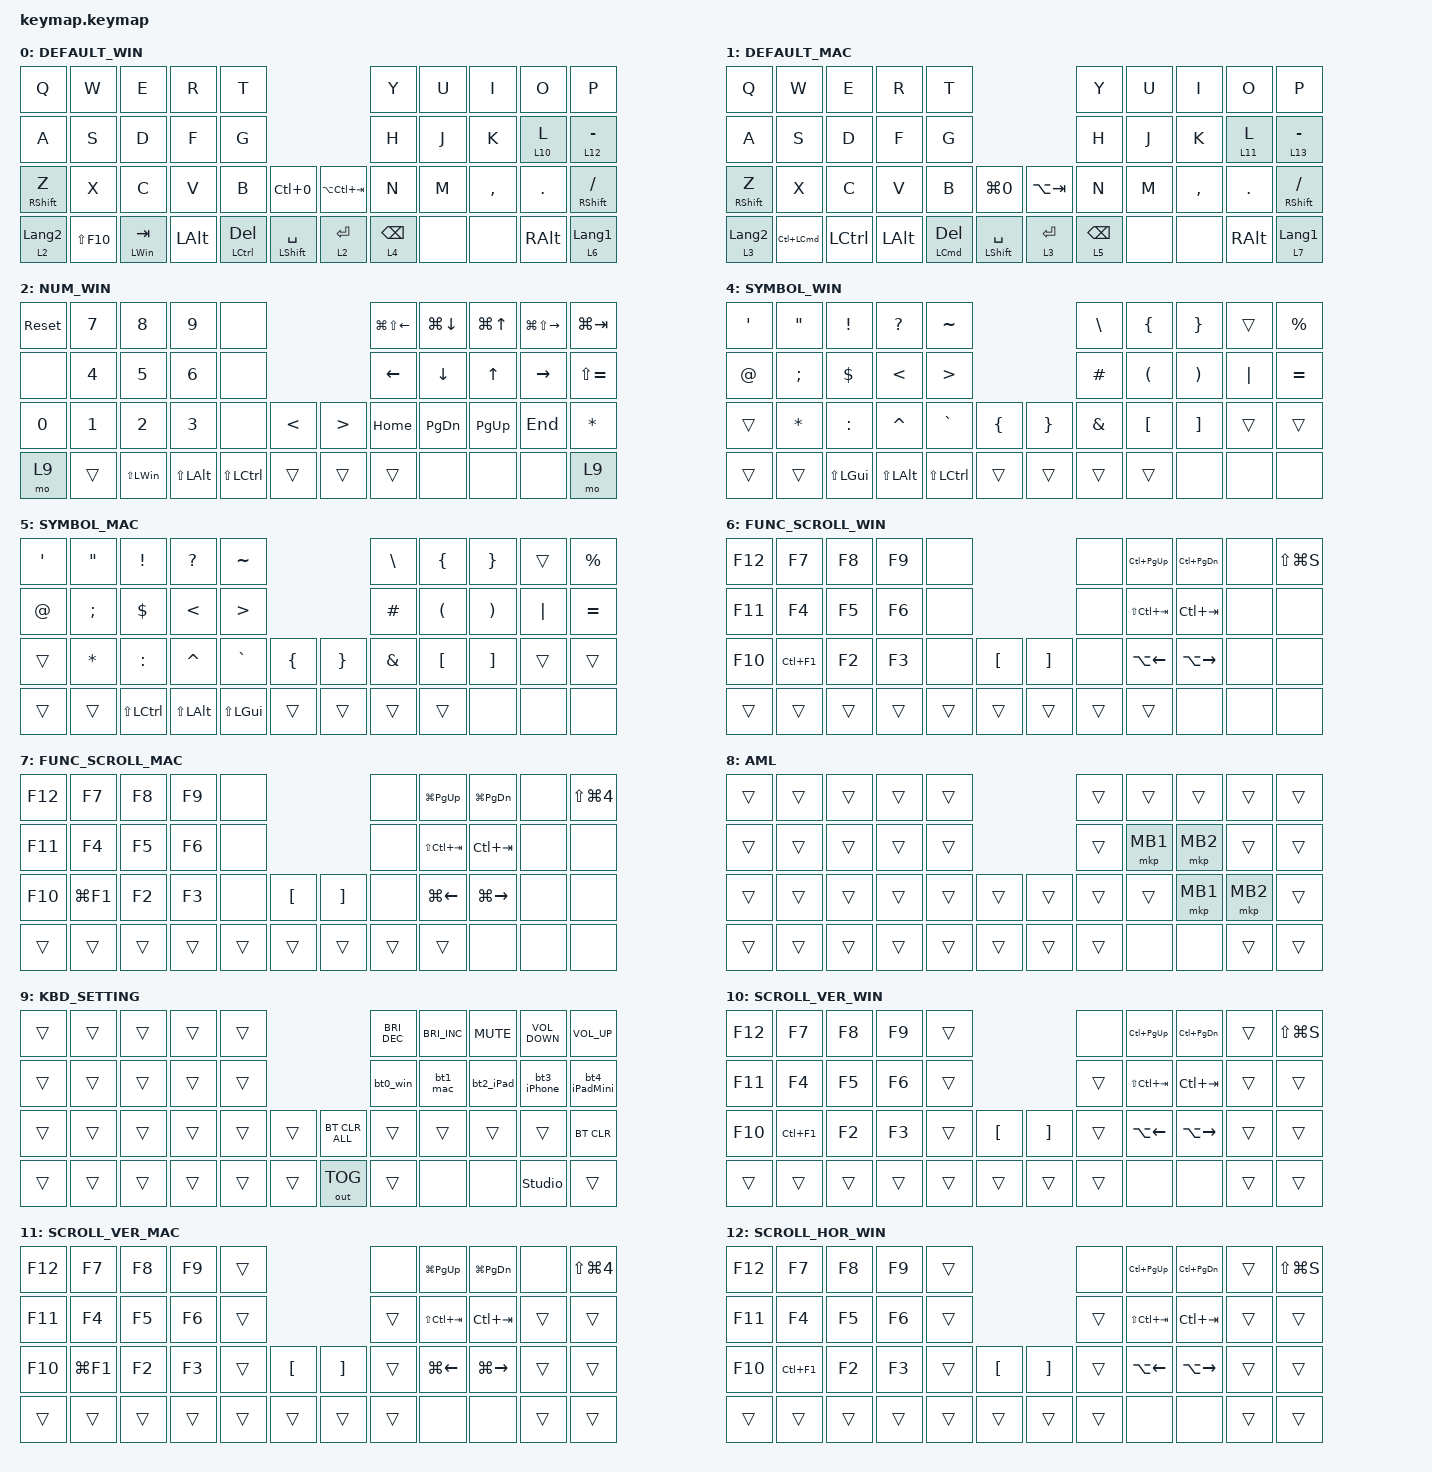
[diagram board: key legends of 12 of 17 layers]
#include <dt-bindings/zmk/input_transform.h>
#include <input/processors.dtsi>
#include <input/processors/report_rate_limit.dtsi>
#include <scroll-snap.dtsi>
#include "elpekenin/behaviors.dtsi"
#include <behaviors/input_gestures_accel.dtsi>
#include <behaviors/runtime_macro.dtsi>
#include <behaviors.dtsi>
#include <dt-bindings/zmk/bt.h>
#include <dt-bindings/zmk/keys.h>
#include <dt-bindings/zmk/outputs.h>
#include <dt-bindings/zmk/pointing.h>

#define DEFAULT_WIN 0
#define DEFAULT_MAC 1
#define NUM_WIN 2
#define NUM_MAC 3
#define SYMBOL_WIN 4
#define SYMBOL_MAC 5
#define FUNC_SCROLL_WIN 6
#define FUNC_SCROLL_MAC 7
#define AML 8
#define KBD_SETTING 9
#define SCROLL_VER_WIN 10
#define SCROLL_VER_MAC 11
#define SCROLL_HOR_WIN 12
#define SCROLL_HOR_MAC 13
#define GESTURE_WIN 14
#define GESTURE_MAC 15
#define WIN_SCROLL_DIR 16

#undef ZMK_POINTING_DEFAULT_SCRL_VAL

#define ZMK_POINTING_DEFAULT_SCRL_VAL 30

#define MOD_MORPH(NAME, NORMAL, MORPHED, MODS_VAL) \
    NAME: NAME { \
        compatible = "zmk,behavior-mod-morph"; \
        #binding-cells = <0>; \
        bindings = <NORMAL>, <MORPHED>; \
        mods = <MODS_VAL>; \
    };
#define MOD_MORPH_KEEP(NAME, NORMAL, MORPHED, MODS_VAL, KEEP_VAL) \
    NAME: NAME { \
        compatible = "zmk,behavior-mod-morph"; \
        #binding-cells = <0>; \
        bindings = <NORMAL>, <MORPHED>; \
        mods = <MODS_VAL>; \
        keep-mods = <KEEP_VAL>; \
    };

// XSレイアウト（Sレイアウト, 44キー）を選択

// ZMK_KEYMAP_LEN uses the largest enabled physical layout's transform.
// This keymap only supports S; keep M/L available to other keymaps.
&physical_layout_m {
    status = "disabled";
};

&physical_layout_l {
    status = "disabled";
};

/ {
    chosen { zmk,physical-layout = &physical_layout_s; };

    /omit-if-no-ref/
    tb_scroll_runtime: tb_scroll_runtime {
        compatible = "zmk,input-processor-runtime";
        processor-label = "tbscrl";
        type = <INPUT_EV_REL>;
        x-codes = <INPUT_REL_HWHEEL>;
        y-codes = <INPUT_REL_WHEEL>;
        scale-multiplier = <1>;
        scale-divisor = <1>;
        rotation-degrees = <0>;
        track-remainders;
        #input-processor-cells = <0>;
    };
};

&zip_scroll_snap {
    x-threshold = <3 4>;
    y-threshold = <4 3>;
    xy-threshold = <3 4>;
    require-n-samples = <4>;
    immediate-snap-threshold = <800>;
    lock-duration-ms = <150>;
    lock-for-next-n-events = <4>;
    idle-reset-timeout-ms = <800>;
};

&mmv {
    delay-ms = <20>;
    time-to-max-speed-ms = <300>;
    acceleration-exponent = <2>;
};

&msc {
    delay-ms = <0>;
    time-to-max-speed-ms = <500>;
    acceleration-exponent = <2>;
};

&mkp_input_listener { input-processors = <&zip_temp_layer AML 250>; };

&mt {
    flavor = "balanced";
    tapping-term-ms = <180>;
    quick-tap-ms = <180>;
};

&lt {
    tapping-term-ms = <180>;
    quick-tap-ms = <180>;
};

&sl { release-after-ms = <30000>; };

// トラックボール入力リスナー設定（XY反転はハードウェア依存のため維持）

&pointing_listener {
    // レポートレート制限 + Threshold付きAML

    input-processors =
        <&zip_xy_transform (INPUT_TRANSFORM_X_INVERT | INPUT_TRANSFORM_Y_INVERT)>,
        <&zip_report_rate_limit 8>,
        <&zip_temp_layer_threshold AML 30000>,
        <&pointer_accel>,
        <&mouse_runtime_input_processor>;

    // 自由スクロール（Mac）

    scroller_mac {
        layers = <FUNC_SCROLL_MAC>;
        input-processors =
            <&zip_scroll_acceleration 6>,
            <&zip_xy_scaler 1 8>,
            <&zip_xy_transform INPUT_TRANSFORM_X_INVERT>,
            <&zip_xy_to_scroll_mapper>,
            <&tb_scroll_runtime>;

        // <&zip_scroll_snap>;
    };

    // 自由スクロール（Windows）

    scroller_win {
        layers = <FUNC_SCROLL_WIN>;
        input-processors =
            <&zip_scroll_acceleration 6>,
            <&zip_xy_scaler 1 2>,
            <&zip_xy_transform INPUT_TRANSFORM_Y_INVERT>,
            <&zip_xy_to_scroll_mapper>,
            <&tb_scroll_runtime>;

        // <&zip_scroll_snap>;
    };

    // 縦スクロール（Mac）

    scroller_mac_vertical {
        layers = <SCROLL_VER_MAC>;
        input-processors =
            <&zip_scroll_acceleration 6>,
            <&zip_y_scaler 1 8>,
            <&zip_x_scaler 0 1>,
            <&zip_xy_to_scroll_mapper>,
            <&tb_scroll_runtime>;
    };

    // 横スクロール（Mac）

    scroller_mac_horizontal {
        layers = <SCROLL_HOR_MAC>;
        input-processors =
            <&zip_scroll_acceleration 6>,
            <&zip_x_scaler 1 8>,
            <&zip_y_scaler 0 1>,
            <&zip_xy_transform INPUT_TRANSFORM_X_INVERT>,
            <&zip_xy_to_scroll_mapper>,
            <&tb_scroll_runtime>;
    };

    // 縦スクロール（Windows）

    scroller_win_vertical {
        layers = <SCROLL_VER_WIN>;
        input-processors =
            <&zip_scroll_acceleration 6>,
            <&zip_y_scaler 1 2>,
            <&zip_x_scaler 0 1>,
            <&zip_xy_transform INPUT_TRANSFORM_Y_INVERT>,
            <&zip_xy_to_scroll_mapper>,
            <&tb_scroll_runtime>;
    };

    // 横スクロール（Windows）

    scroller_win_horizontal {
        layers = <SCROLL_HOR_WIN>;
        input-processors =
            <&zip_scroll_acceleration 6>,
            <&zip_x_scaler 1 2>,
            <&zip_y_scaler 0 1>,
            <&zip_xy_to_scroll_mapper>,
            <&tb_scroll_runtime>;
    };

    // トラックボール→矢印キー変換（数字レイヤー）

    arrow_keys {
        layers = <NUM_WIN NUM_MAC>;
        input-processors = <&zip_arrow_keys>;
        process-next;
    };

    // 音量・輝度調整（KBD_SETTINGレイヤー）

    volume_keys {
        layers = <KBD_SETTING>;
        input-processors = <&zip_volume_keys>;
        process-next;
    };

    // カーソル無効（数字・設定レイヤー）

    post_volume_keys {
        layers = <NUM_WIN NUM_MAC KBD_SETTING>;
        input-processors = <&zip_xy_scaler 0 1>;
    };
};

/ {
    /omit-if-no-ref/

    zip_temp_layer: zip_temp_layer {
        compatible = "zmk,input-processor-temp-layer";
        #input-processor-cells = <2>;
        excluded-positions = <
            16  // J
            17  // K
            36  // Delete (Ctrl/Cmd+Del位置)
            37  // Space (Shift+Space位置)
        >;

        require-prior-idle-ms = <300>;
    };

    zip_temp_layer_threshold: zip_temp_layer_threshold {
        compatible = "zmk,input-processor-temp-layer-threshold";
        #input-processor-cells = <2>;
        threshold = <12>;
        excluded-positions = <
            16  // J
            17  // K
            29  // ,
            30  // .
            36  // Delete
            37  // Space
        >;

        require-prior-idle-ms = <0>;
        reset-timeout-ms = <200>;
    };

    zip_scroll_acceleration: zip_scroll_acceleration {
        compatible = "zmk,input-processor-scroll-acceleration";
        #input-processor-cells = <1>;
        decay-ms = <100>;
        max-acceleration = <20>;
        min-speed-threshold = <1>;
    };

    pointer_accel: pointer_accel {
        compatible = "zmk,input-processor-acceleration";
        #input-processor-cells = <0>;
        input-type = <INPUT_EV_REL>;
        codes = <INPUT_REL_X INPUT_REL_Y>;
    };

    zip_arrow_keys: zip_arrow_keys {
        compatible = "zmk,input-processor-keybind";
        #input-processor-cells = <0>;
        track_remainders;
        bindings = <&kp LEFT>, <&kp RIGHT>, <&kp DOWN>, <&kp UP>;

        tick = <10>;
        wait-ms = <5>;
        tap-ms = <5>;
        mode = <1>;
    };

    zip_volume_keys: zip_volume_keys {
        compatible = "zmk,input-processor-keybind";
        #input-processor-cells = <0>;
        track_remainders;
        bindings =
            <&kp C_VOLUME_DOWN>,
            <&kp C_VOLUME_UP>,
            <&kp C_BRIGHTNESS_DEC>,
            <&kp C_BRIGHTNESS_INC>;

        tick = <6>;                     // 低速時の感度を上げる（10→6: 少ない移動で1ステップ）
        wait-ms = <25>;                 // 高速時の連続発火を抑える（5→25: 一気に変化しすぎない）
        max_pending_activations = <3>;  // 1報告で貯まる上限を絞る（既定5→3: 高速時の上振れ抑制）
        tap-ms = <5>;
        mode = <1>;
    };

    combos {
        compatible = "zmk,combos";

        // S+D → Tab（roBa: 11+12 = S+D, torabo同じ）

        tab {
            bindings = <&kp TAB>;
            key-positions = <11 12>;
            timeout-ms = <80>;
        };

        // D+F → Shift+Tab

        shift_tab {
            bindings = <&kp LS(TAB)>;
            key-positions = <12 13>;
            timeout-ms = <80>;
        };

        // Q+W → Escape

        Esc {
            bindings = <&kp ESCAPE>;
            key-positions = <0 1>;
            timeout-ms = <80>;
        };

        // J+K → 中クリック（roBa: 18+19, torabo: 16+17）

        middle_click {
            bindings = <&mkp MB3>;
            key-positions = <16 17>;
        };

        // A+S → CapsLock（roBa: 10+11, torabo同じ）

        caps_lock {
            bindings = <&kp CAPSLOCK>;
            key-positions = <10 11>;
        };

        middle_click_alt {
            bindings = <&mkp MB3>;
            key-positions = <29 30>;
        };
    };

    macros {
        to_layer_0: to_layer_0 {
            compatible = "zmk,behavior-macro-one-param";
            #binding-cells = <1>;
            bindings = <&to 0 &macro_param_1to1 &kp MACRO_PLACEHOLDER>;
            label = "TO_LAYER_0";
        };

        bt0_win: bt0 {
            compatible = "zmk,behavior-macro";
            #binding-cells = <0>;
            bindings =
                <&bt BT_SEL 0 &bt BT_DISC 1 &bt BT_DISC 2 &bt BT_DISC 3 &bt BT_DISC 4>,
                <&macro_wait_time 200>,
                <&df 0 &tog_on WIN_SCROLL_DIR>;

            label = "BT0";
        };

        bt1_mac: bt1 {
            compatible = "zmk,behavior-macro";
            #binding-cells = <0>;
            bindings =
                <&bt BT_SEL 1 &bt BT_DISC 0 &bt BT_DISC 2 &bt BT_DISC 3 &bt BT_DISC 4>,
                <&macro_wait_time 200>,
                <&df 1 &tog_off WIN_SCROLL_DIR>;

            label = "BT1";
        };

        bt2_iPad: bt2_iPad {
            compatible = "zmk,behavior-macro";
            #binding-cells = <0>;
            bindings =
                <&bt BT_SEL 2 &bt BT_DISC 0 &bt BT_DISC 1 &bt BT_DISC 3 &bt BT_DISC 4>,
                <&macro_wait_time 200>,
                <&df 1 &tog_off WIN_SCROLL_DIR>;

            label = "BT2_IPAD";
        };

        bt3_iPhone: bt3_iPhone {
            compatible = "zmk,behavior-macro";
            #binding-cells = <0>;
            bindings =
                <&bt BT_SEL 3 &bt BT_DISC 0 &bt BT_DISC 1 &bt BT_DISC 2 &bt BT_DISC 4>,
                <&macro_wait_time 200>,
                <&df 1 &tog_off WIN_SCROLL_DIR>;

            label = "BT3_IPHONE";
        };

        bt4_iPadMini: bt4_iPadMini {
            compatible = "zmk,behavior-macro";
            #binding-cells = <0>;
            bindings =
                <&bt BT_SEL 4 &bt BT_DISC 0 &bt BT_DISC 1 &bt BT_DISC 2 &bt BT_DISC 3>,
                <&macro_wait_time 200>,
                <&df 1 &tog_off WIN_SCROLL_DIR>;

            label = "BT4_IPADMINI";
        };

        to_scroll_layer_win: to_scroll_layer_win {
            compatible = "zmk,behavior-macro";
            #binding-cells = <0>;
            bindings =
                <&to FUNC_SCROLL_WIN>,
                <&macro_press>,
                <&mo FUNC_SCROLL_WIN>,
                <&macro_pause_for_release>,
                <&macro_release>,
                <&mo FUNC_SCROLL_WIN>;

            label = "TO_SCROLL_LAYER_WIN";
        };

        to_scroll_layer_mac: to_scroll_layer_mac {
            compatible = "zmk,behavior-macro";
            #binding-cells = <0>;
            bindings =
                <&to FUNC_SCROLL_MAC>,
                <&macro_press>,
                <&mo FUNC_SCROLL_MAC>,
                <&macro_pause_for_release>,
                <&macro_release>,
                <&mo FUNC_SCROLL_MAC>;

            label = "TO_SCROLL_LAYER_MAC";
        };

        exit_AML: exit_AML {
            compatible = "zmk,behavior-macro";
            wait-ms = <0>;
            tap-ms = <0>;
            #binding-cells = <0>;
            bindings = <&tog_off AML>;
            label = "exit_AML";
        };

        kp_exit_AML: kp_exit_AML {
            compatible = "zmk,behavior-macro-one-param";
            wait-ms = <0>;
            tap-ms = <0>;
            #binding-cells = <1>;
            bindings = <&macro_param_1to1 &kp MACRO_PLACEHOLDER &exit_AML>;
            label = "KP_exit_AML";
        };

        move_window_left_max: move_window_left_max {
            compatible = "zmk,behavior-macro";
            #binding-cells = <0>;
            bindings =
                <&kp LG(LEFT)>,
                <&macro_wait_time 20>,
                <&kp LG(RIGHT)>,
                <&macro_wait_time 20>,
                <&kp LS(LG(LEFT))>,
                <&macro_wait_time 50>,
                <&kp LG(UP_ARROW)>;

            label = "MOVE_WINDOW_LEFT_MAX";
        };

        move_window_right_max: move_window_right_max {
            compatible = "zmk,behavior-macro";
            #binding-cells = <0>;
            bindings =
                <&kp LG(LEFT)>,
                <&macro_wait_time 20>,
                <&kp LG(RIGHT)>,
                <&macro_wait_time 20>,
                <&kp LS(LG(RIGHT))>,
                <&macro_wait_time 50>,
                <&kp LG(UP_ARROW)>;

            label = "MOVE_WINDOW_RIGHT_MAX";
        };
    };

    behaviors {
        lt_to_layer_0: lt_to_layer_0 {
            compatible = "zmk,behavior-hold-tap";
            label = "LAYER_TAP_TO_0";
            bindings = <&mo>, <&to_layer_0>;

            #binding-cells = <2>;
            tapping-term-ms = <200>;
        };

        mt_exit_AML_on_tap: mt_exit_AML_on_tap {
            compatible = "zmk,behavior-hold-tap";
            label = "MT_exit_AML_ON_TAP";
            bindings = <&kp>, <&kp_exit_AML>;

            #binding-cells = <2>;
            tapping-term-ms = <200>;
            flavor = "tap-preferred";
            quick-tap-ms = <100>;
        };

        tog_on: toggle_layer_on_only {
            compatible = "zmk,behavior-toggle-layer";
            #binding-cells = <1>;
            display-name = "Toggle Layer On";
            toggle-mode = "on";
        };

        tog_off: toggle_layer_off_only {
            compatible = "zmk,behavior-toggle-layer";
            #binding-cells = <1>;
            display-name = "Toggle Layer Off";
            toggle-mode = "off";
        };

        sands: space_and_shift {
            compatible = "zmk,behavior-hold-tap";
            label = "SPACE_AND_SHIFT";
            #binding-cells = <2>;
            flavor = "tap-unless-interrupted";
            tapping-term-ms = <220>;
            quick-tap-ms = <125>;
            global-quick-tap;
            bindings = <&kp>, <&kp>;
        };

        lt_tap_pref: lt_tap_pref {
            compatible = "zmk,behavior-hold-tap";
            label = "LT_TAP_PREF";
            bindings = <&mo>, <&kp>;

            #binding-cells = <2>;
            tapping-term-ms = <180>;
            quick-tap-ms = <180>;
            flavor = "tap-preferred";
        };

        // Shift+, → !

        shift_comma: shift_comma {
            compatible = "zmk,behavior-mod-morph";
            #binding-cells = <0>;
            bindings = <&mt LEFT_ALT COMMA>, <&kp EXCLAMATION>;

            mods = <(MOD_LSFT)>;
        };

        // Shift+. → ?（Windows）

        shift_period_win: shift_period_win {
            compatible = "zmk,behavior-mod-morph";
            #binding-cells = <0>;
            bindings = <&mt LCTRL PERIOD>, <&kp QUESTION>;

            mods = <(MOD_LSFT)>;
        };

        // Shift+. → ?（Mac）

        shift_period_mac: shift_period_mac {
            compatible = "zmk,behavior-mod-morph";
            #binding-cells = <0>;
            bindings = <&mt LEFT_GUI DOT>, <&kp QUESTION>;

            mods = <(MOD_LSFT)>;
        };

        // Shift+/ → backslash

        shift_slash: shift_slash {
            compatible = "zmk,behavior-mod-morph";
            #binding-cells = <0>;
            bindings = <&mt RIGHT_SHIFT SLASH>, <&kp BACKSLASH>;

            mods = <(MOD_LSFT)>;
            label = "SHIFT_SLASH";
        };

        TD_0_win: TD_0_win {
            compatible = "zmk,behavior-tap-dance";
            label = "TD_0_WIN";
            #binding-cells = <0>;
            bindings = <&lt 10 MINUS>, <&lt 12 LS(EQUAL)>;

            tapping-term-ms = <170>;
        };

        TD_0_mac: TD_0_mac {
            compatible = "zmk,behavior-tap-dance";
            label = "TD_0_MAC";
            #binding-cells = <0>;
            bindings = <&lt 11 MINUS>, <&lt 13 LS(EQUAL)>;

            tapping-term-ms = <170>;
        };
    };

    keymap {
        compatible = "zmk,keymap";

        // レイヤー0: デフォルト（Windows）
        // torabo Sレイアウト 44キー
        // pos: 0-9(Row1), 10-19(Row2), 20-31(Row3, 25/26=inner), 32-43(Row4/thumb)

        DEFAULT_WIN {
            display-name = "DEFAULT_WIN";
            bindings = <
&kp Q             &kp W        &kp E             &kp R         &kp T                                                        &kp Y            &kp U  &kp I      &kp O          &kp P
&kp A             &kp S        &kp D             &kp F         &kp G                                                        &kp H            &kp J  &kp K      &lt 10 L       &lt 12 MINUS
&mt RSHIFT Z      &kp X        &kp C             &kp V         &kp B             &kp LC(N0)                &kp LA(LC(TAB))  &kp N            &kp M  &kp COMMA  &kp PERIOD     &mt RSHIFT SLASH
&lt 2 LANGUAGE_2  &kp LS(F10)  &mt LEFT_WIN TAB  &kp LEFT_ALT  &mt LCTRL DELETE  &mt LEFT_SHIFT SPACE      &lt 2 ENTER      &lt 4 BACKSPACE  &none  &none      &kp RIGHT_ALT  &lt 6 LANGUAGE_1
            >;
        };

        // レイヤー1: デフォルト（Mac）

        DEFAULT_MAC {
            display-name = "DEFAULT_MAC";
            bindings = <
&kp Q             &kp W                 &kp E      &kp R         &kp T                                                           &kp Y            &kp U  &kp I      &kp O          &kp P
&kp A             &kp S                 &kp D      &kp F         &kp G                                                           &kp H            &kp J  &kp K      &lt 11 L       &lt 13 MINUS
&mt RSHIFT Z      &kp X                 &kp C      &kp V         &kp B                    &kp LG(N0)                &kp LA(TAB)  &kp N            &kp M  &kp COMMA  &kp PERIOD     &mt RSHIFT SLASH
&lt 3 LANGUAGE_2  &kp LC(LEFT_COMMAND)  &kp LCTRL  &kp LEFT_ALT  &mt LEFT_COMMAND DELETE  &mt LEFT_SHIFT SPACE      &lt 3 ENTER  &lt 5 BACKSPACE  &none  &none      &kp RIGHT_ALT  &lt 7 LANGUAGE_1
            >;
        };

        // レイヤー2: 数字（Windows）

        NUM_WIN {
            display-name = "NUM_WIN";
            bindings = <
&sys_reset    &kp NUMBER_7  &kp NUMBER_8      &kp NUMBER_9      &none                                                      &kp LG(LS(LEFT))  &kp LG(DOWN)   &kp LG(UP_ARROW)  &kp LG(LS(RIGHT))  &kp LG(TAB)
&none         &kp NUMBER_4  &kp NUMBER_5      &kp NUMBER_6      &none                                                      &kp LEFT          &kp DOWN       &kp UP            &kp RIGHT          &kp LS(EQUAL)
&kp NUMBER_0  &kp NUMBER_1  &kp NUMBER_2      &kp NUMBER_3      &none                 &kp LESS_THAN      &kp GREATER_THAN  &kp HOME          &kp PAGE_DOWN  &kp PAGE_UP       &kp END            &kp ASTERISK
&mo 9         &trans        &kp LS(LEFT_WIN)  &kp LS(LEFT_ALT)  &kp LS(LEFT_CONTROL)  &trans             &trans            &trans            &none          &none             &none              &mo 9
            >;
        };

        // レイヤー3: 数字（Mac）

        NUM_MAC {
            display-name = "NUM_MAC";
            bindings = <
&sys_reset  &kp N7                  &kp N8                &kp N9            &none                                                  &kp LC(LA(LG(LEFT)))  &kp LC(DOWN)  &kp LC(UP_ARROW)  &kp LC(LA(LG(RIGHT)))  &kp LC(LA(ENTER))
&none       &kp N4                  &kp N5                &kp N6            &none                                                  &kp LEFT              &kp DOWN      &kp UP            &kp RIGHT              &kp LS(EQUAL)
&kp N0      &kp N1                  &kp N2                &kp N3            &none             &kp LESS_THAN      &kp GREATER_THAN  &kp LG(LEFT)          &kp LG(DOWN)  &kp LG(UP)        &kp LG(RIGHT)          &kp ASTERISK
&mo 9       &kp LC(LG(LEFT_SHIFT))  &kp LS(LEFT_CONTROL)  &kp LS(LEFT_ALT)  &kp LS(LEFT_GUI)  &trans             &trans            &trans                &none         &none             &none                  &mo 9
            >;
        };

        // レイヤー4: 記号（Windows）

        SYMBOL_WIN {
            display-name = "SYMBOL_WIN";
            bindings = <
&kp SQT      &kp DOUBLE_QUOTES  &kp EXCLAMATION   &kp QUESTION      &kp TILDE                                              &kp BACKSLASH  &kp LEFT_BRACE        &kp RIGHT_BRACE        &trans    &kp PERCENT
&kp AT_SIGN  &kp SEMICOLON      &kp DOLLAR        &kp LESS_THAN     &kp GREATER_THAN                                       &kp HASH       &kp LEFT_PARENTHESIS  &kp RIGHT_PARENTHESIS  &kp PIPE  &kp EQUAL
&trans       &kp ASTERISK       &kp COLON         &kp CARET         &kp GRAVE         &kp LEFT_BRACE      &kp RIGHT_BRACE  &kp AMPERSAND  &kp LEFT_BRACKET      &kp RIGHT_BRACKET      &trans    &trans
&trans       &trans             &kp LS(LEFT_GUI)  &kp LS(LEFT_ALT)  &kp LS(LCTRL)     &trans              &trans           &trans         &trans                &none                  &none     &none
            >;
        };

        // レイヤー5: 記号（Mac）

        SYMBOL_MAC {
            display-name = "SYMBOL_MAC";
            bindings = <
&kp SQT      &kp DOUBLE_QUOTES  &kp EXCLAMATION  &kp QUESTION      &kp TILDE                                              &kp BACKSLASH  &kp LEFT_BRACE        &kp RIGHT_BRACE        &trans    &kp PERCENT
&kp AT_SIGN  &kp SEMICOLON      &kp DOLLAR       &kp LESS_THAN     &kp GREATER_THAN                                       &kp HASH       &kp LEFT_PARENTHESIS  &kp RIGHT_PARENTHESIS  &kp PIPE  &kp EQUAL
&trans       &kp ASTERISK       &kp COLON        &kp CARET         &kp GRAVE         &kp LEFT_BRACE      &kp RIGHT_BRACE  &kp AMPERSAND  &kp LEFT_BRACKET      &kp RIGHT_BRACKET      &trans    &trans
&trans       &trans             &kp LS(LCTRL)    &kp LS(LEFT_ALT)  &kp LS(LEFT_GUI)  &trans              &trans           &trans         &trans                &none                  &none     &none
            >;
        };

        // レイヤー6: ファンクション+スクロール（Windows）

        FUNC_SCROLL_WIN {
            display-name = "FUNC_SCROLL_WIN";
            bindings = <
&kp F12  &kp F7      &kp F8  &kp F9  &none                                            &none   &kp LC(PAGE_UP)  &kp LC(PAGE_DOWN)  &none  &kp LS(LG(S))
&kp F11  &kp F4      &kp F5  &kp F6  &none                                            &none   &kp LS(LC(TAB))  &kp LC(TAB)        &none  &none
&kp F10  &kp LC(F1)  &kp F2  &kp F3  &none   &kp LEFT_BRACKET      &kp RIGHT_BRACKET  &none   &kp LA(LEFT)     &kp LA(RIGHT)      &none  &none
&trans   &trans      &trans  &trans  &trans  &trans                &trans             &trans  &trans           &none              &none  &none
            >;
        };

        // レイヤー7: ファンクション+スクロール（Mac）

        FUNC_SCROLL_MAC {
            display-name = "FUNC_SCROLL_MAC";
            bindings = <
&kp F12  &kp F7      &kp F8  &kp F9  &none                                            &none   &kp LG(PAGE_UP)  &kp LG(PAGE_DOWN)  &none  &kp LS(LG(NUMBER_4))
&kp F11  &kp F4      &kp F5  &kp F6  &none                                            &none   &kp LS(LC(TAB))  &kp LC(TAB)        &none  &none
&kp F10  &kp LG(F1)  &kp F2  &kp F3  &none   &kp LEFT_BRACKET      &kp RIGHT_BRACKET  &none   &kp LG(LEFT)     &kp LG(RIGHT)      &none  &none
&trans   &trans      &trans  &trans  &trans  &trans                &trans             &trans  &trans           &none              &none  &none
            >;
        };

        // レイヤー8: 自動マウスレイヤー（AML）

        AML {
            display-name = "AML";
            bindings = <
&trans  &trans  &trans  &trans  &trans                      &trans  &trans    &trans    &trans    &trans
&trans  &trans  &trans  &trans  &trans                      &trans  &mkp MB1  &mkp MB2  &trans    &trans
&trans  &trans  &trans  &trans  &trans  &trans      &trans  &trans  &trans    &mkp MB1  &mkp MB2  &trans
&trans  &trans  &trans  &trans  &trans  &trans      &trans  &trans  &none     &none     &trans    &trans
            >;
        };

        // レイヤー9: キーボード設定

        KBD_SETTING {
            display-name = "KBD_SETTING";
            bindings = <
&trans  &trans  &trans  &trans  &trans                              &kp C_BRIGHTNESS_DEC  &kp C_BRIGHTNESS_INC  &kp K_MUTE  &kp C_VOLUME_DOWN  &kp C_VOLUME_UP
&trans  &trans  &trans  &trans  &trans                              &bt0_win              &bt1_mac              &bt2_iPad   &bt3_iPhone        &bt4_iPadMini
&trans  &trans  &trans  &trans  &trans  &trans      &bt BT_CLR_ALL  &trans                &trans                &trans      &trans             &bt BT_CLR
&trans  &trans  &trans  &trans  &trans  &trans      &out OUT_TOG    &trans                &none                 &none       &studio_unlock     &trans
            >;
        };

        // レイヤー10: 縦スクロール（Windows）

        SCROLL_VER_WIN {
            display-name = "SCROLL_VER_WIN";
            bindings = <
&kp F12  &kp F7      &kp F8  &kp F9  &trans                                           &none   &kp LC(PAGE_UP)  &kp LC(PAGE_DOWN)  &trans  &kp LS(LG(S))
&kp F11  &kp F4      &kp F5  &kp F6  &trans                                           &trans  &kp LS(LC(TAB))  &kp LC(TAB)        &trans  &trans
&kp F10  &kp LC(F1)  &kp F2  &kp F3  &trans  &kp LEFT_BRACKET      &kp RIGHT_BRACKET  &trans  &kp LA(LEFT)     &kp LA(RIGHT)      &trans  &trans
&trans   &trans      &trans  &trans  &trans  &trans                &trans             &trans  &none            &none              &trans  &trans
            >;
        };

        // レイヤー11: 縦スクロール（Mac）

        SCROLL_VER_MAC {
            display-name = "SCROLL_VER_MAC";
            bindings = <
&kp F12  &kp F7      &kp F8  &kp F9  &trans                                           &none   &kp LG(PAGE_UP)  &kp LG(PAGE_DOWN)  &none   &kp LS(LG(NUMBER_4))
&kp F11  &kp F4      &kp F5  &kp F6  &trans                                           &trans  &kp LS(LC(TAB))  &kp LC(TAB)        &trans  &trans
&kp F10  &kp LG(F1)  &kp F2  &kp F3  &trans  &kp LEFT_BRACKET      &kp RIGHT_BRACKET  &trans  &kp LG(LEFT)     &kp LG(RIGHT)      &trans  &trans
&trans   &trans      &trans  &trans  &trans  &trans                &trans             &trans  &none            &none              &trans  &trans
            >;
        };

        // レイヤー12: 横スクロール（Windows）

        SCROLL_HOR_WIN {
            display-name = "SCROLL_HOR_WIN";
            bindings = <
&kp F12  &kp F7      &kp F8  &kp F9  &trans                                           &none   &kp LC(PAGE_UP)  &kp LC(PAGE_DOWN)  &trans  &kp LS(LG(S))
&kp F11  &kp F4      &kp F5  &kp F6  &trans                                           &trans  &kp LS(LC(TAB))  &kp LC(TAB)        &trans  &trans
&kp F10  &kp LC(F1)  &kp F2  &kp F3  &trans  &kp LEFT_BRACKET      &kp RIGHT_BRACKET  &trans  &kp LA(LEFT)     &kp LA(RIGHT)      &trans  &trans
&trans   &trans      &trans  &trans  &trans  &trans                &trans             &trans  &none            &none              &trans  &trans
            >;
        };

        // レイヤー13: 横スクロール（Mac）

        SCROLL_HOR_MAC {
            display-name = "SCROLL_HOR_MAC";
            bindings = <
&kp F12  &kp F7      &kp F8  &kp F9  &trans                                           &none   &kp LG(PAGE_UP)  &kp LG(PAGE_DOWN)  &none   &kp LS(LG(NUMBER_4))
&kp F11  &kp F4      &kp F5  &kp F6  &trans                                           &trans  &kp LS(LC(TAB))  &kp LC(TAB)        &trans  &trans
&kp F10  &kp LG(F1)  &kp F2  &kp F3  &trans  &kp LEFT_BRACKET      &kp RIGHT_BRACKET  &trans  &kp LG(LEFT)     &kp LG(RIGHT)      &trans  &trans
&trans   &trans      &trans  &trans  &trans  &trans                &trans             &trans  &none            &none              &trans  &trans
            >;
        };

        // レイヤー14: ジェスチャー（Windows）

        GESTURE_WIN {
            display-name = "GESTURE_WIN";
            bindings = <
&trans  &trans  &trans  &trans  &trans                      &trans  &trans  &trans  &trans  &trans
&trans  &trans  &trans  &trans  &trans                      &trans  &trans  &trans  &trans  &trans
&trans  &trans  &trans  &trans  &trans  &trans      &trans  &trans  &trans  &trans  &trans  &trans
&trans  &trans  &trans  &trans  &trans  &trans      &trans  &trans  &none   &none   &trans  &trans
            >;
        };

        // レイヤー15: ジェスチャー（Mac）

        GESTURE_MAC {
            display-name = "GESTURE_MAC";
            bindings = <
&trans  &trans  &trans  &trans  &trans                      &trans  &trans  &trans  &trans  &trans
&trans  &trans  &trans  &trans  &trans                      &trans  &trans  &trans  &trans  &trans
&trans  &trans  &trans  &trans  &trans  &trans      &trans  &trans  &trans  &trans  &trans  &trans
&trans  &trans  &trans  &trans  &trans  &trans      &trans  &trans  &none   &none   &trans  &trans
            >;
        };

        // レイヤー16: WIN_SCROLL_DIR（Winスクロール方向トグル）
        // bt0_win で tog_on、bt1_mac/bt2_iPad/bt3_iPhone で tog_off

        WIN_SCROLL_DIR {
            display-name = "WIN_SCROLL_DIR";
            bindings = <
&trans  &trans  &trans  &trans  &trans                      &trans  &trans  &trans  &trans  &trans
&trans  &trans  &trans  &trans  &trans                      &trans  &trans  &trans  &trans  &trans
&trans  &trans  &trans  &trans  &trans  &trans      &trans  &trans  &trans  &trans  &trans  &trans
&trans  &trans  &trans  &trans  &trans  &trans      &trans  &trans  &none   &none   &trans  &trans
            >;
        };
    };

    conditional_layers {
        compatible = "zmk,conditional-layers";

        Gesture_win {
            if-layers = <10 12>;
            then-layer = <14>;
        };

        Gesture_mac {
            if-layers = <11 13>;
            then-layer = <15>;
        };
    };
};
